# HT32F12365_66 register map
File version: 1.1
CPU: CM3 r2p0, little endian, no MPU, no FPU, 4 interrupt priority bits
Registers are 32-bit, read-write, reset 0x0 unless marked. A register's access mark holds for its fields unless they carry their own. Offsets are from the block's base; [hi:lo] are bit positions; {n}, {i} and the like mark numbered series.

## USB
Base 0x400A8000
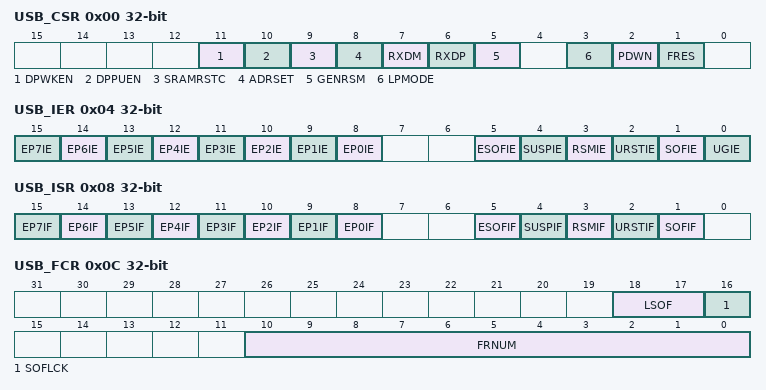
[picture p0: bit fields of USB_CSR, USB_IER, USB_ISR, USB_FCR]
0x00 USB_CSR
  [11] DPWKEN, [10] DPPUEN, [9] SRAMRSTC, [8] ADRSET, [7] RXDM, [6] RXDP, [5] GENRSM, [3] LPMODE, [2] PDWN, [1] FRES
0x04 USB_IER
  [n+8] EP{n}IE (n=0..7), [5] ESOFIE, [4] SUSPIE, [3] RSMIE, [2] URSTIE, [1] SOFIE, [0] UGIE
0x08 USB_ISR
  [n+8] EP{n}IF (n=0..7), [5] ESOFIF, [4] SUSPIF, [3] RSMIF, [2] URSTIF, [1] SOFIF
0x0C USB_FCR
  [18:17] LSOF, [16] SOFLCK, [10:0] FRNUM
0x10 USB_DEVAR
  [6:0] DEVA
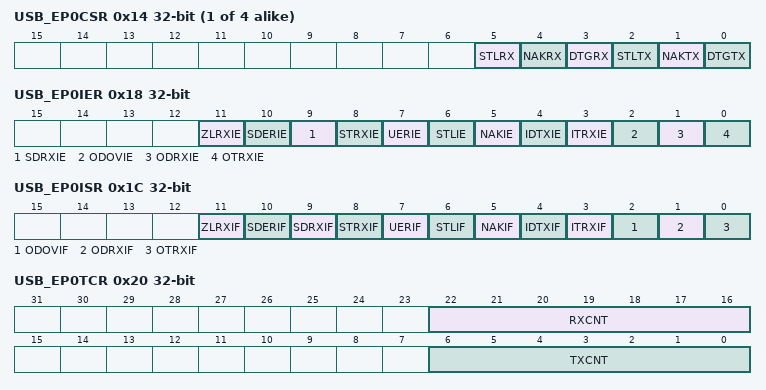
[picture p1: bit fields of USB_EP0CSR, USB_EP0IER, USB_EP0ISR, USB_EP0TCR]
{0x14+0x14*i} USB_EP{i}CSR (i=0..3)
  [5] STLRX, [4] NAKRX, [3] DTGRX, [2] STLTX, [1] NAKTX, [0] DTGTX
0x18 USB_EP0IER
  [11] ZLRXIE, [10] SDERIE, [9] SDRXIE, [8] STRXIE, [7] UERIE, [6] STLIE, [5] NAKIE, [4] IDTXIE, [3] ITRXIE, [2] ODOVIE, [1] ODRXIE, [0] OTRXIE
0x1C USB_EP0ISR
  [11] ZLRXIF, [10] SDERIF, [9] SDRXIF, [8] STRXIF, [7] UERIF, [6] STLIF, [5] NAKIF, [4] IDTXIF, [3] ITRXIF, [2] ODOVIF, [1] ODRXIF, [0] OTRXIF
0x20 USB_EP0TCR
  [22:16] RXCNT, [6:0] TXCNT
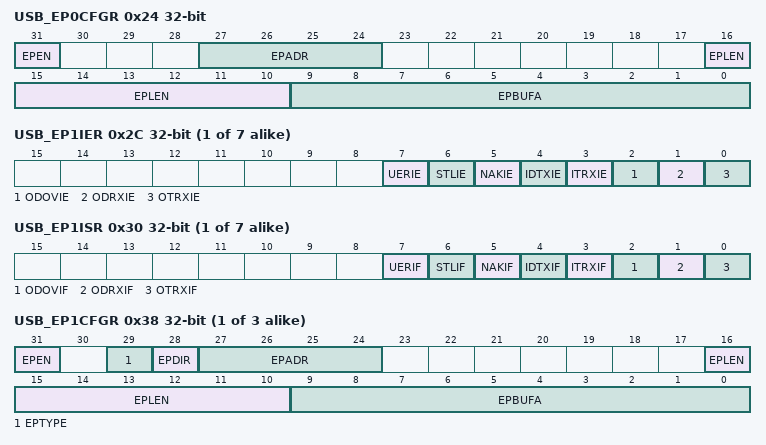
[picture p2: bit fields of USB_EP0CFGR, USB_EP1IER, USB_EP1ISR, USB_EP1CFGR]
0x24 USB_EP0CFGR
  [31] EPEN, [27:24] EPADR, [16:10] EPLEN, [9:0] EPBUFA
{0x18+0x14*i} USB_EP{i}IER (i=1..7)
  [7] UERIE, [6] STLIE, [5] NAKIE, [4] IDTXIE, [3] ITRXIE, [2] ODOVIE, [1] ODRXIE, [0] OTRXIE
{0x1C+0x14*i} USB_EP{i}ISR (i=1..7)
  [7] UERIF, [6] STLIF, [5] NAKIF, [4] IDTXIF, [3] ITRXIF, [2] ODOVIF, [1] ODRXIF, [0] OTRXIF
{0x20+0x14*i} USB_EP{i}TCR (i=1..3)
  [8:0] TCNT
{0x24+0x14*i} USB_EP{i}CFGR (i=1..3)
  [31] EPEN, [29] EPTYPE, [28] EPDIR, [27:24] EPADR, [16:10] EPLEN, [9:0] EPBUFA
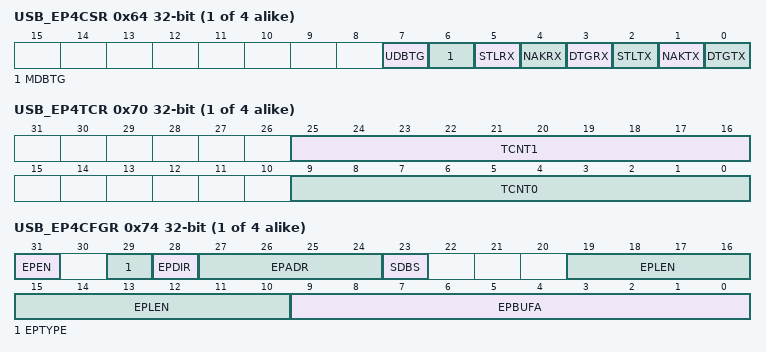
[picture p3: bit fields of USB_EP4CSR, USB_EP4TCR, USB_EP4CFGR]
{0x14+0x14*i} USB_EP{i}CSR (i=4..7)
  [7] UDBTG, [6] MDBTG, [5] STLRX, [4] NAKRX, [3] DTGRX, [2] STLTX, [1] NAKTX, [0] DTGTX
{0x20+0x14*i} USB_EP{i}TCR (i=4..7)
  [25:16] TCNT1, [9:0] TCNT0
{0x24+0x14*i} USB_EP{i}CFGR (i=4..7)
  [31] EPEN, [29] EPTYPE, [28] EPDIR, [27:24] EPADR, [23] SDBS, [19:10] EPLEN, [9:0] EPBUFA

## PDMA
Base 0x40090000
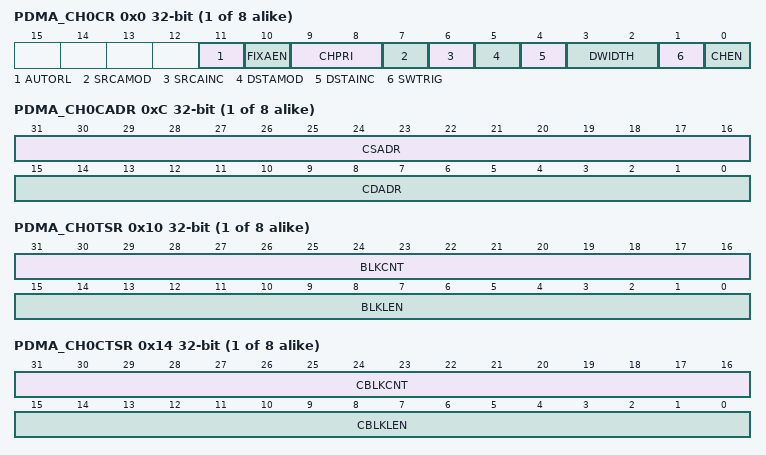
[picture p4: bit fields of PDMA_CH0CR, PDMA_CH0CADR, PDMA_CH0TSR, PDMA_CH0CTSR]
{0x0+0x18*i} PDMA_CH{i}CR (i=0..7)
  [11] AUTORL, [10] FIXAEN, [9:8] CHPRI, [7] SRCAMOD, [6] SRCAINC, [5] DSTAMOD, [4] DSTAINC, [3:2] DWIDTH, [1] SWTRIG, [0] CHEN
{0x4+0x18*i} PDMA_CH{i}SADR (i=0..7)
  [31:0] SADR
{0x8+0x18*i} PDMA_CH{i}DADR (i=0..7)
  [31:0] DADR
{0xC+0x18*i} PDMA_CH{i}CADR (i=0..7)
  [31:16] CSADR, [15:0] CDADR
{0x10+0x18*i} PDMA_CH{i}TSR (i=0..7)
  [31:16] BLKCNT, [15:0] BLKLEN
{0x14+0x18*i} PDMA_CH{i}CTSR (i=0..7)
  [31:16] CBLKCNT, [15:0] CBLKLEN
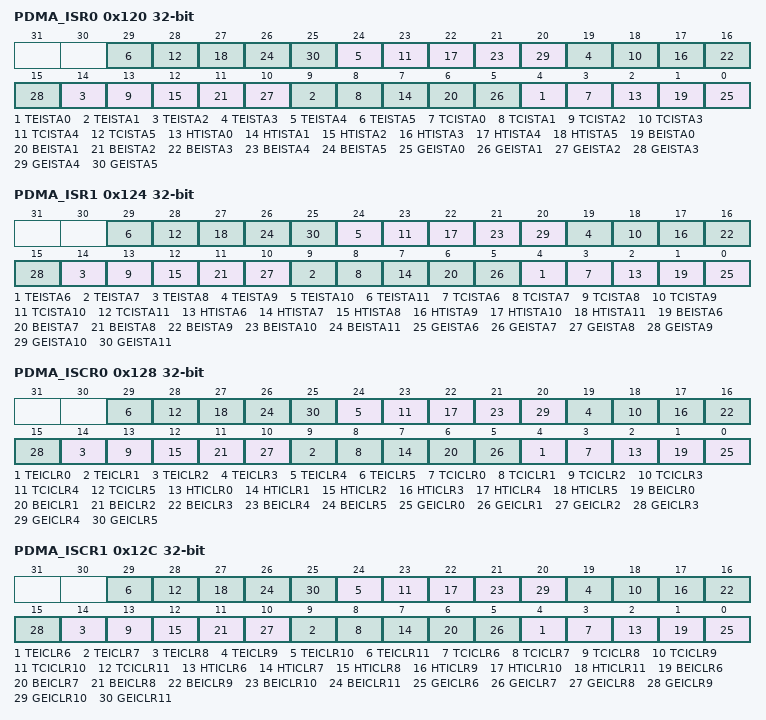
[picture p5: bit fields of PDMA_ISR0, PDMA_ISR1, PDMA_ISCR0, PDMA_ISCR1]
0x120 PDMA_ISR0
  [5n+4] TEISTA{n} (n=0..5), [5n+3] TCISTA{n} (n=0..5), [5n+2] HTISTA{n} (n=0..5), [5n+1] BEISTA{n} (n=0..5), [5n] GEISTA{n} (n=0..5)
0x124 PDMA_ISR1
  [5n-26] TEISTA{n} (n=6..11), [5n-27] TCISTA{n} (n=6..11), [5n-28] HTISTA{n} (n=6..11), [5n-29] BEISTA{n} (n=6..11), [5n-30] GEISTA{n} (n=6..11)
0x128 PDMA_ISCR0
  [5n+4] TEICLR{n} (n=0..5), [5n+3] TCICLR{n} (n=0..5), [5n+2] HTICLR{n} (n=0..5), [5n+1] BEICLR{n} (n=0..5), [5n] GEICLR{n} (n=0..5)
0x12C PDMA_ISCR1
  [5n-26] TEICLR{n} (n=6..11), [5n-27] TCICLR{n} (n=6..11), [5n-28] HTICLR{n} (n=6..11), [5n-29] BEICLR{n} (n=6..11), [5n-30] GEICLR{n} (n=6..11)
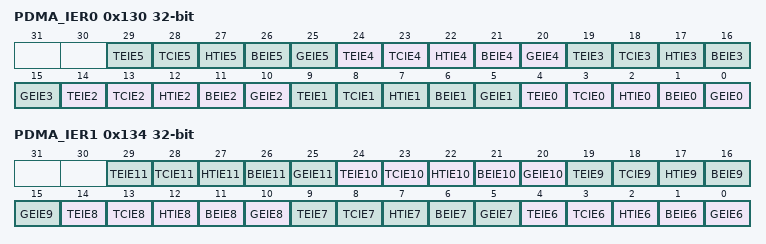
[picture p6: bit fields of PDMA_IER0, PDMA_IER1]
0x130 PDMA_IER0
  [5n+4] TEIE{n} (n=0..5), [5n+3] TCIE{n} (n=0..5), [5n+2] HTIE{n} (n=0..5), [5n+1] BEIE{n} (n=0..5), [5n] GEIE{n} (n=0..5)
0x134 PDMA_IER1
  [5n-26] TEIE{n} (n=6..11), [5n-27] TCIE{n} (n=6..11), [5n-28] HTIE{n} (n=6..11), [5n-29] BEIE{n} (n=6..11), [5n-30] GEIE{n} (n=6..11)

## EBI
Base 0x40098000
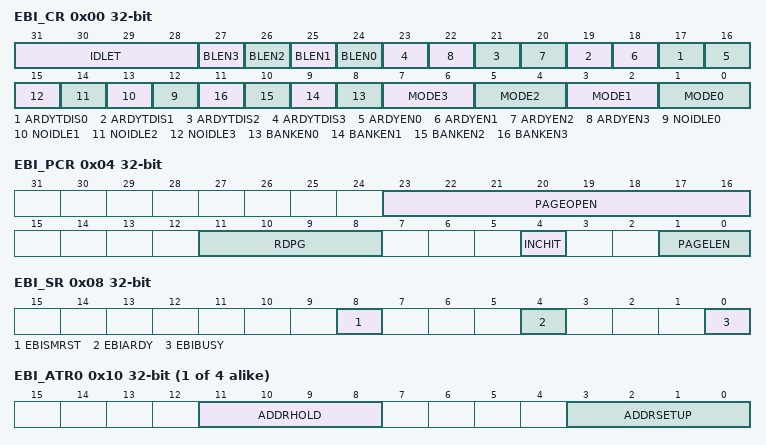
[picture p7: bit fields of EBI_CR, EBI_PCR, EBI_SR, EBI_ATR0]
0x00 EBI_CR
  [31:28] IDLET, [n+24] BLEN{n} (n=0..3), [2n+17] ARDYTDIS{n} (n=0..3), [2n+16] ARDYEN{n} (n=0..3), [n+12] NOIDLE{n} (n=0..3), [n+8] BANKEN{n} (n=0..3), [2n+1:2n] MODE{n} (n=0..3)
0x04 EBI_PCR
  [23:16] PAGEOPEN, [11:8] RDPG, [4] INCHIT, [1:0] PAGELEN
0x08 EBI_SR
  [8] EBISMRST, [4] EBIARDY, [0] EBIBUSY
{0x10+0x10*i} EBI_ATR{i} (i=0..3)
  [11:8] ADDRHOLD, [3:0] ADDRSETUP
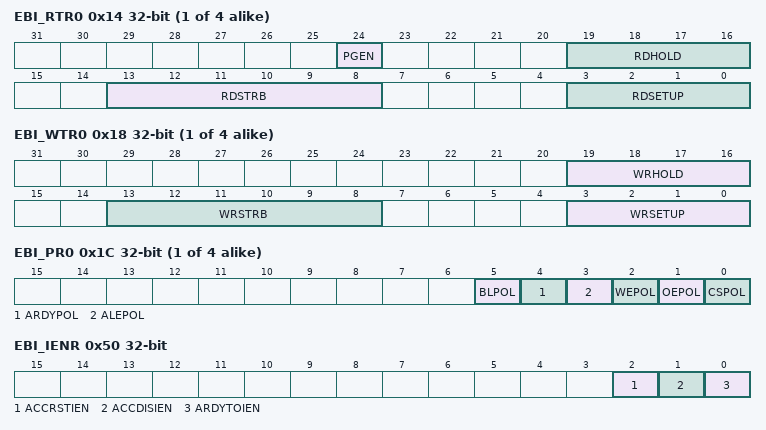
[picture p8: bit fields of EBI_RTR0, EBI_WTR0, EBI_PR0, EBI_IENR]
{0x14+0x10*i} EBI_RTR{i} (i=0..3)
  [24] PGEN, [19:16] RDHOLD, [13:8] RDSTRB, [3:0] RDSETUP
{0x18+0x10*i} EBI_WTR{i} (i=0..3)
  [19:16] WRHOLD, [13:8] WRSTRB, [3:0] WRSETUP
{0x1C+0x10*i} EBI_PR{i} (i=0..3)
  [5] BLPOL, [4] ARDYPOL, [3] ALEPOL, [2] WEPOL, [1] OEPOL, [0] CSPOL
0x50 EBI_IENR
  [2] ACCRSTIEN, [1] ACCDISIEN, [0] ARDYTOIEN
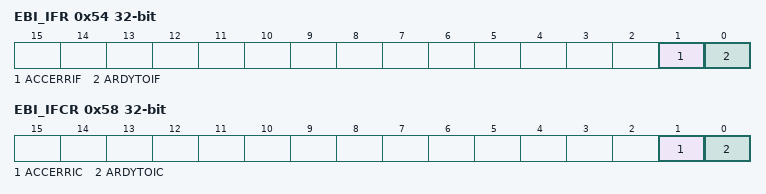
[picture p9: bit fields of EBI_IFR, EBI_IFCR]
0x54 EBI_IFR
  [1] ACCERRIF, [0] ARDYTOIF
0x58 EBI_IFCR
  [1] ACCERRIC, [0] ARDYTOIC

## I2S
Base 0x40026000
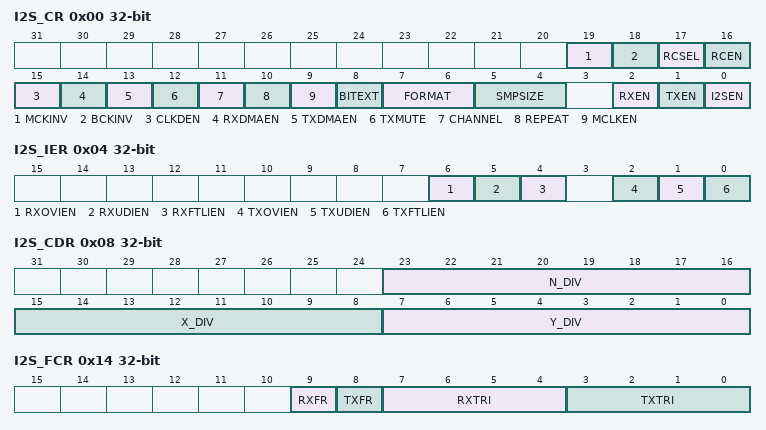
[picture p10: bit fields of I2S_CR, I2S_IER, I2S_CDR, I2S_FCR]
0x00 I2S_CR
  [19] MCKINV, [18] BCKINV, [17] RCSEL, [16] RCEN, [15] CLKDEN, [14] RXDMAEN, [13] TXDMAEN, [12] TXMUTE, [11] CHANNEL, [10] REPEAT, [9] MCLKEN, [8] BITEXT, [7:6] FORMAT, [5:4] SMPSIZE, [2] RXEN, [1] TXEN, [0] I2SEN
0x04 I2S_IER
  [6] RXOVIEN, [5] RXUDIEN, [4] RXFTLIEN, [2] TXOVIEN, [1] TXUDIEN, [0] TXFTLIEN
0x08 I2S_CDR
  [23:16] N_DIV, [15:8] X_DIV, [7:0] Y_DIV
0x0C I2S_TXDR
0x10 I2S_RXDR
0x14 I2S_FCR
  [9] RXFR, [8] TXFR, [7:4] RXTRI, [3:0] TXTRI
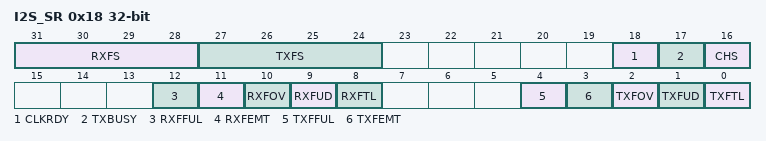
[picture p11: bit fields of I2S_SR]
0x18 I2S_SR
  [31:28] RXFS, [27:24] TXFS, [18] CLKRDY, [17] TXBUSY, [16] CHS, [12] RXFFUL, [11] RXFEMT, [10] RXFOV, [9] RXFUD, [8] RXFTL, [4] TXFFUL, [3] TXFEMT, [2] TXFOV, [1] TXFUD, [0] TXFTL
0x1C I2S_RCNTR

## CRC
Base 0x4008A000
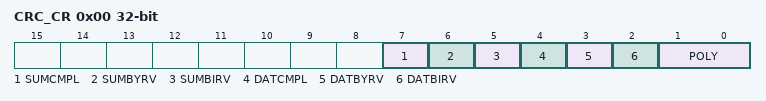
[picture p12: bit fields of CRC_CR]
0x00 CRC_CR
  [7] SUMCMPL, [6] SUMBYRV, [5] SUMBIRV, [4] DATCMPL, [3] DATBYRV, [2] DATBIRV, [1:0] POLY
0x04 CRC_SDR
  [31:0] SEED
0x08 CRC_CSR
  [31:0] CHKSUM
0x0C CRC_DR
  [31:0] DATA
